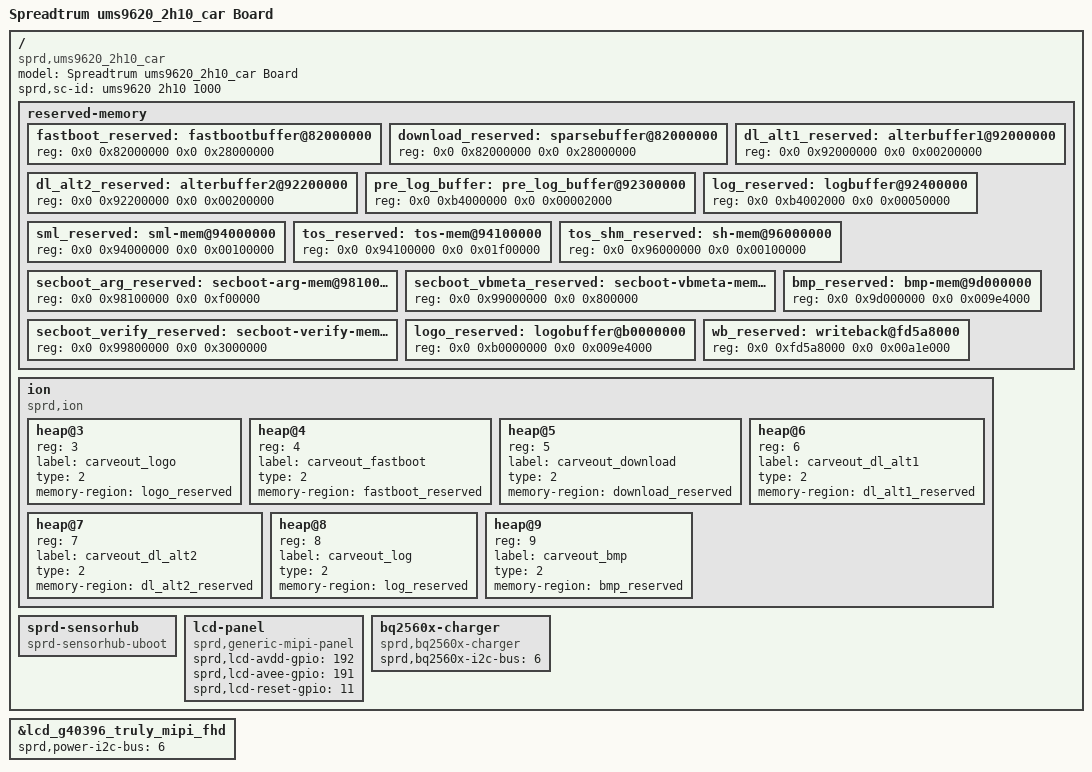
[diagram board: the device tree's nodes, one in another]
/*
 * Spreadtrum UMS9620 board DTS file
 *
 * Copyright (C) 2016, Spreadtrum Communications Inc.
 *
 * This file is licensed under a dual GPLv2 or X11 license.
 */

/dts-v1/;

#include "ums9620.dtsi"
#include "lcd/lcd_g40396_truly_mipi_fhd.dtsi"
#include "lcd/lcd_ili7806s_truly_mipi_hdplus.dtsi"
#include "lcd/lcd_dummy_mipi.dtsi"

/ {
	model = "Spreadtrum ums9620_2h10_car Board";

	compatible = "sprd,ums9620_2h10_car";

	sprd,sc-id = "ums9620 2h10 1000";

	reserved-memory {
		#address-cells = <2>;
		#size-cells = <2>;
		ranges;

		fastboot_reserved: fastbootbuffer@82000000{
			reg = <0x0 0x82000000 0x0 0x28000000>;
		};

		download_reserved: sparsebuffer@82000000{
			reg = <0x0 0x82000000 0x0 0x28000000>;
		};

		dl_alt1_reserved: alterbuffer1@92000000{
			reg = <0x0 0x92000000 0x0 0x00200000>;
		};

		dl_alt2_reserved: alterbuffer2@92200000{
			reg = <0x0 0x92200000 0x0 0x00200000>;
		};

		pre_log_buffer: pre_log_buffer@92300000{
			reg = <0x0 0xb4000000 0x0 0x00002000>;
		};

		log_reserved: logbuffer@92400000{
			reg = <0x0 0xb4002000 0x0 0x00050000>;
		};

		/* must be 4K aligned */
		sml_reserved: sml-mem@94000000{
			reg = <0x0 0x94000000 0x0 0x00100000>;
		};

		tos_reserved: tos-mem@94100000{
			reg = <0x0 0x94100000 0x0 0x01f00000>;
		};

		tos_shm_reserved: sh-mem@96000000{
			reg = <0x0 0x96000000 0x0 0x00100000>;
		};

		secboot_arg_reserved: secboot-arg-mem@98100000{
			reg = <0x0 0x98100000 0x0 0xf00000>;
		};

		secboot_vbmeta_reserved: secboot-vbmeta-mem@99000000{
			reg = <0x0 0x99000000 0x0 0x800000>;
		};

		secboot_verify_reserved: secboot-verify-mem@99800000{
			reg = <0x0 0x99800000 0x0 0x3000000>;
		};

		bmp_reserved: bmp-mem@9d000000 {
			reg = <0x0 0x9d000000 0x0 0x009e4000>;
		};

		/* 1080x2400x4Bytes & 4K alignment*/
		logo_reserved: logobuffer@b0000000{
			reg = <0x0 0xb0000000 0x0 0x009e4000>;
		};

		wb_reserved: writeback@fd5a8000 {
			reg = <0x0 0xfd5a8000 0x0 0x00a1e000>;
		};
	};

	ion {
		compatible = "sprd,ion";
		#address-cells = <1>;
		#size-cells = <0>;

		heap@3 {
			reg = <3>;
			label = "carveout_logo";
			type = <2>;
			memory-region = <&logo_reserved>;
		};

		heap@4 {
			reg = <4>;
			label = "carveout_fastboot";
			type = <2>;
			memory-region = <&fastboot_reserved>;
		};

		heap@5 {
			reg = <5>;
			label = "carveout_download";
			type = <2>;
			memory-region = <&download_reserved>;
		};

		heap@6 {
			reg = <6>;
			label = "carveout_dl_alt1";
			type = <2>;
			memory-region = <&dl_alt1_reserved>;
		};

		heap@7 {
			reg = <7>;
			label = "carveout_dl_alt2";
			type = <2>;
			memory-region = <&dl_alt2_reserved>;
		};

		heap@8 {
			reg = <8>;
			label = "carveout_log";
			type = <2>;
			memory-region = <&log_reserved>;
		};

		heap@9 {
			reg = <9>;
			label = "carveout_bmp";
			type = <2>;
			memory-region = <&bmp_reserved>;
		};
	};

	sprd-sensorhub {
		compatible = "sprd-sensorhub-uboot";
	};

	lcd-panel {
		compatible = "sprd,generic-mipi-panel";
		sprd,lcd-avdd-gpio = <192>;
		sprd,lcd-avee-gpio = <191>;
		sprd,lcd-reset-gpio = <11>;
	};

	bq2560x-charger {
		compatible = "sprd,bq2560x-charger";
		sprd,bq2560x-i2c-bus = <6>;
	};
};

&lcd_g40396_truly_mipi_fhd {
	sprd,power-i2c-bus = <6>;
};
